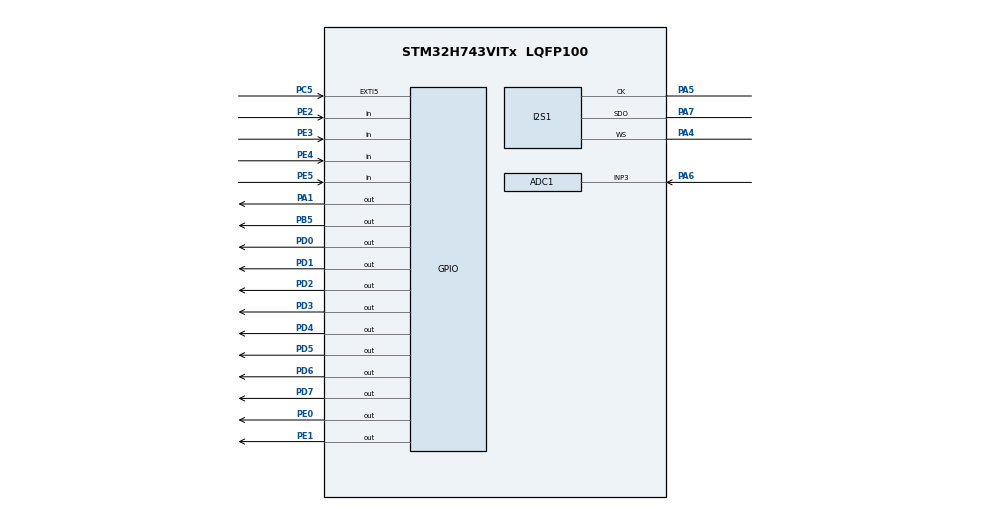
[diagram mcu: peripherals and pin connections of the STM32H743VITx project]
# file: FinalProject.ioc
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ADC1.Channel-2\#ChannelRegularConversion=ADC_CHANNEL_3
ADC1.NbrOfConversionFlag=1
ADC1.OffsetNumber-2\#ChannelRegularConversion=ADC_OFFSET_NONE
ADC1.OffsetSignedSaturation-2\#ChannelRegularConversion=DISABLE
ADC1.Rank-2\#ChannelRegularConversion=1
ADC1.SamplingTime-2\#ChannelRegularConversion=ADC_SAMPLETIME_1CYCLE_5
ADC1.master=1
I2S1.AudioFreq=AudioFreqCustomValue
I2S1.AudioFreqCustom=20000
I2S1.Data24BitAlignment=I2S_DATA_24BIT_ALIGNMENT_RIGHT
I2S1.DataFormat=I2S_DATAFORMAT_16B
I2S1.ErrorAudioFreq=0.0 %
I2S1.Instance=SPI$Index
I2S1.MasterKeepIOState=I2S_MASTER_KEEP_IO_STATE_DISABLE
I2S1.RealAudioFreq=20.0 KHz
I2S1.Standard=I2S_STANDARD_PHILIPS
Mcu.Family=STM32H7
Mcu.Name=STM32H743VITx
Mcu.Package=LQFP100
NVIC.EXTI9_5_IRQn=true\:0\:0\:false\:false\:true\:true\:true
NVIC.PriorityGroup=NVIC_PRIORITYGROUP_4
NVIC.TIM16_IRQn=true\:0\:0\:false\:false\:true\:true\:true
PA1.Signal=GPIO_Output
PA4.Mode=Half_Duplex_Master_Tx
PA4.Signal=I2S1_WS
PA5.Mode=Half_Duplex_Master_Tx
PA5.Signal=I2S1_CK
PA6.Signal=ADCx_INP3
PA7.Mode=Half_Duplex_Master_Tx
PA7.Signal=I2S1_SDO
PB5.Signal=GPIO_Output
PC5.GPIO_ModeDefaultEXTI=GPIO_MODE_IT_FALLING
PC5.GPIO_PuPd=GPIO_PULLUP
PC5.Signal=GPXTI5
PD0.Signal=GPIO_Output
PD1.Signal=GPIO_Output
PD2.Signal=GPIO_Output
PD3.Signal=GPIO_Output
PD4.Signal=GPIO_Output
PD5.Signal=GPIO_Output
PD6.Signal=GPIO_Output
PD7.Signal=GPIO_Output
PE0.Signal=GPIO_Output
PE1.Signal=GPIO_Output
PE2.Signal=GPIO_Input
PE3.Signal=GPIO_Input
PE4.Signal=GPIO_Input
PE5.Signal=GPIO_Input
ProjectManager.HeapSize=0x200
ProjectManager.StackSize=0x400
ProjectManager.TargetToolchain=STM32CubeIDE
RCC.ADCFreq_Value=37500000
RCC.APB1Freq_Value=64000000
RCC.APB2Freq_Value=64000000
RCC.APB3Freq_Value=64000000
RCC.APB4Freq_Value=64000000
RCC.CortexFreq_Value=64000000
RCC.DIVM1=4
RCC.DIVM2=4
RCC.DIVM3=10
RCC.DIVN1=11
RCC.DIVN2=9
RCC.DIVP2=4
RCC.DIVQ3=16
RCC.DIVR3=4
RCC.HCLKFreq_Value=64000000
RCC.PLL2FRACN=3072
RCC.PLLFRACN=328
RCC.SYSCLKFreq_VALUE=64000000
RCC.USBCLockSelection=RCC_USBCLKSOURCE_PLL3
RCC.USBFreq_Value=51600000
SH.ADCx_INP3.0=ADC1_INP3,IN3-Single-Ended
TIM16.AutoReloadPreload=TIM_AUTORELOAD_PRELOAD_DISABLE
TIM16.Period=40 - 1
TIM16.Prescaler=80 - 1
VP_TIM16_VS_ClockSourceINT.Mode=Enable_Timer
board=custom

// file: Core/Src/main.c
/* USER CODE BEGIN Header */
/**
  ******************************************************************************
  * @file           : main.c
  * @brief          : Main program body
  ******************************************************************************
  * @attention
  *
  * Copyright (c) 2022 STMicroelectronics.
  * All rights reserved.
  *
  * This software is licensed under terms that can be found in the LICENSE file
  * in the root directory of this software component.
  * If no LICENSE file comes with this software, it is provided AS-IS.
  *
  ******************************************************************************
  */
/* USER CODE END Header */
#include "main.h"
#include "adc.h"
#include "i2s.h"
#include "tim.h"
#include "gpio.h"

/* USER CODE BEGIN Includes */
#include "custom.h"
/* USER CODE END Includes */

void SystemClock_Config(void);

int main(void)
{

  /* MCU Configuration--------------------------------------------------------*/

  /* Reset of all peripherals, Initializes the Flash interface and the Systick. */
  HAL_Init();

  /* Configure the system clock */
  SystemClock_Config();

  /* Initialize all configured peripherals */
  MX_GPIO_Init();
  MX_I2S1_Init();
  MX_ADC1_Init();
  MX_TIM16_Init();
  /* USER CODE BEGIN 2 */

  customSetup(hadc1, hi2s1);
  HAL_TIM_Base_Start_IT(&htim16);
  /* USER CODE END 2 */

  /* Infinite loop */
  /* USER CODE BEGIN WHILE */
  while (1)
  {
	customLoop();
    /* USER CODE END WHILE */

  }
}

void SystemClock_Config(void)
{
  RCC_OscInitTypeDef RCC_OscInitStruct = {0};
  RCC_ClkInitTypeDef RCC_ClkInitStruct = {0};

  /** Supply configuration update enable
  */
  HAL_PWREx_ConfigSupply(PWR_LDO_SUPPLY);
  /** Configure the main internal regulator output voltage
  */
  __HAL_PWR_VOLTAGESCALING_CONFIG(PWR_REGULATOR_VOLTAGE_SCALE3);

  while(!__HAL_PWR_GET_FLAG(PWR_FLAG_VOSRDY)) {}
  /** Macro to configure the PLL clock source
  */
  __HAL_RCC_PLL_PLLSOURCE_CONFIG(RCC_PLLSOURCE_HSI);
  /** Initializes the RCC Oscillators according to the specified parameters
  * in the RCC_OscInitTypeDef structure.
  */
  RCC_OscInitStruct.OscillatorType = RCC_OSCILLATORTYPE_HSI;
  RCC_OscInitStruct.HSIState = RCC_HSI_DIV1;
  RCC_OscInitStruct.HSICalibrationValue = RCC_HSICALIBRATION_DEFAULT;
  RCC_OscInitStruct.PLL.PLLState = RCC_PLL_ON;
  RCC_OscInitStruct.PLL.PLLSource = RCC_PLLSOURCE_HSI;
  RCC_OscInitStruct.PLL.PLLM = 4;
  RCC_OscInitStruct.PLL.PLLN = 11;
  RCC_OscInitStruct.PLL.PLLP = 2;
  RCC_OscInitStruct.PLL.PLLQ = 2;
  RCC_OscInitStruct.PLL.PLLR = 2;
  RCC_OscInitStruct.PLL.PLLRGE = RCC_PLL1VCIRANGE_3;
  RCC_OscInitStruct.PLL.PLLVCOSEL = RCC_PLL1VCOMEDIUM;
  RCC_OscInitStruct.PLL.PLLFRACN = 328;
  if (HAL_RCC_OscConfig(&RCC_OscInitStruct) != HAL_OK)
  {
    Error_Handler();
  }
  /** Initializes the CPU, AHB and APB buses clocks
  */
  RCC_ClkInitStruct.ClockType = RCC_CLOCKTYPE_HCLK|RCC_CLOCKTYPE_SYSCLK
                              |RCC_CLOCKTYPE_PCLK1|RCC_CLOCKTYPE_PCLK2
                              |RCC_CLOCKTYPE_D3PCLK1|RCC_CLOCKTYPE_D1PCLK1;
  RCC_ClkInitStruct.SYSCLKSource = RCC_SYSCLKSOURCE_HSI;
  RCC_ClkInitStruct.SYSCLKDivider = RCC_SYSCLK_DIV1;
  RCC_ClkInitStruct.AHBCLKDivider = RCC_HCLK_DIV1;
  RCC_ClkInitStruct.APB3CLKDivider = RCC_APB3_DIV1;
  RCC_ClkInitStruct.APB1CLKDivider = RCC_APB1_DIV1;
  RCC_ClkInitStruct.APB2CLKDivider = RCC_APB2_DIV1;
  RCC_ClkInitStruct.APB4CLKDivider = RCC_APB4_DIV1;

  if (HAL_RCC_ClockConfig(&RCC_ClkInitStruct, FLASH_LATENCY_1) != HAL_OK)
  {
    Error_Handler();
  }
}

/* USER CODE BEGIN 4 */
void HAL_TIM_PeriodElapsedCallback(TIM_HandleTypeDef *htim){
	if(htim == &htim16)
		customTimerInterrupt();
}
/* USER CODE END 4 */

void Error_Handler(void)
{
  __disable_irq();
  while (1)
  {
  }
}
